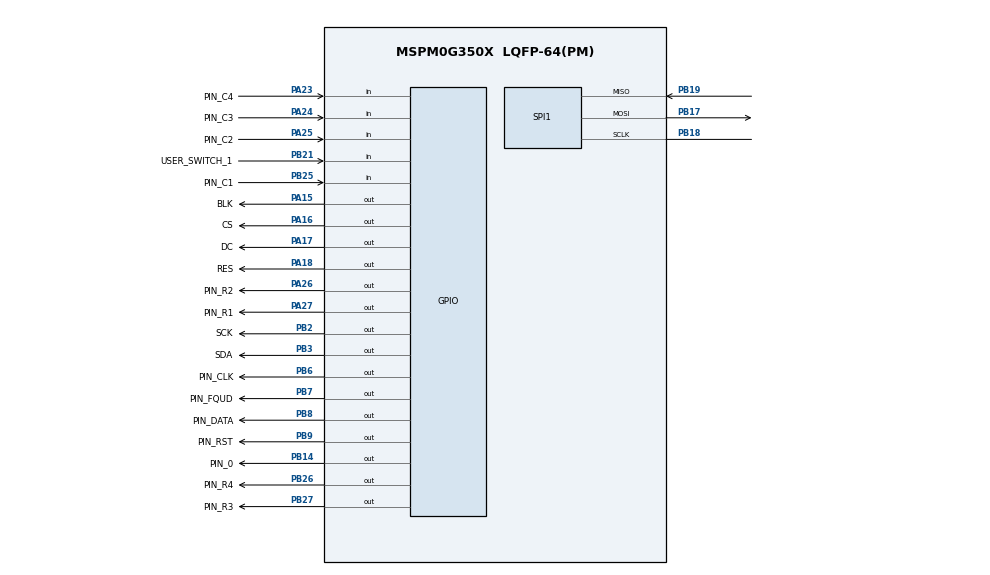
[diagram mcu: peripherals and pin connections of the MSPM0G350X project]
/**
 *
 * @cliArgs --device "MSPM0G350X" --part "Default" --package "LQFP-64(PM)" --product "mspm0_sdk@2.11.00.07"
 * @versions {"tool":"1.28.0+4696"}
 */

/**
 * Import the modules used in this configuration.
 */
const GPIO    = scripting.addModule("/ti/driverlib/GPIO", {}, false);
const GPIO1   = GPIO.addInstance();
const GPIO2   = GPIO.addInstance();
const GPIO3   = GPIO.addInstance();
const GPIO4   = GPIO.addInstance();
const GPIO5   = GPIO.addInstance();
const GPIO6   = GPIO.addInstance();
const SPI     = scripting.addModule("/ti/driverlib/SPI", {}, false);
const SPI1    = SPI.addInstance();
const SYSCTL  = scripting.addModule("/ti/driverlib/SYSCTL");
const SYSTICK = scripting.addModule("/ti/driverlib/SYSTICK");

/**
 * Write custom configuration values to the imported modules.
 */
GPIO1.$name                         = "GPIO_DDS";
GPIO1.associatedPins.create(4);
GPIO1.associatedPins[0].$name       = "PIN_CLK";
GPIO1.associatedPins[0].pin.$assign = "PB6";
GPIO1.associatedPins[1].$name       = "PIN_FQUD";
GPIO1.associatedPins[1].pin.$assign = "PB7";
GPIO1.associatedPins[2].$name       = "PIN_DATA";
GPIO1.associatedPins[2].pin.$assign = "PB8";
GPIO1.associatedPins[3].$name       = "PIN_RST";
GPIO1.associatedPins[3].pin.$assign = "PB9";

const Board = scripting.addModule("/ti/driverlib/Board", {}, false);

GPIO2.$name                         = "GPIO_USRLED";
GPIO2.associatedPins[0].$name       = "PIN_0";
GPIO2.associatedPins[0].pin.$assign = "PB14";

GPIO3.$name                              = "GPIO_KEYMATRIX";
GPIO3.associatedPins.create(8);
GPIO3.associatedPins[0].$name            = "PIN_R1";
GPIO3.associatedPins[0].initialValue     = "SET";
GPIO3.associatedPins[0].pin.$assign      = "PA27";
GPIO3.associatedPins[1].$name            = "PIN_R2";
GPIO3.associatedPins[1].initialValue     = "SET";
GPIO3.associatedPins[1].pin.$assign      = "PA26";
GPIO3.associatedPins[2].$name            = "PIN_R3";
GPIO3.associatedPins[2].initialValue     = "SET";
GPIO3.associatedPins[2].pin.$assign      = "PB27";
GPIO3.associatedPins[3].internalResistor = "PULL_UP";
GPIO3.associatedPins[3].$name            = "PIN_R4";
GPIO3.associatedPins[3].initialValue     = "SET";
GPIO3.associatedPins[3].pin.$assign      = "PB26";
GPIO3.associatedPins[4].direction        = "INPUT";
GPIO3.associatedPins[4].internalResistor = "PULL_UP";
GPIO3.associatedPins[4].$name            = "PIN_C1";
GPIO3.associatedPins[4].pin.$assign      = "PB25";
GPIO3.associatedPins[5].direction        = "INPUT";
GPIO3.associatedPins[5].internalResistor = "PULL_UP";
GPIO3.associatedPins[5].$name            = "PIN_C2";
GPIO3.associatedPins[5].pin.$assign      = "PA25";
GPIO3.associatedPins[6].$name            = "PIN_C3";
GPIO3.associatedPins[6].direction        = "INPUT";
GPIO3.associatedPins[6].internalResistor = "PULL_UP";
GPIO3.associatedPins[6].pin.$assign      = "PA24";
GPIO3.associatedPins[7].$name            = "PIN_C4";
GPIO3.associatedPins[7].direction        = "INPUT";
GPIO3.associatedPins[7].internalResistor = "PULL_UP";
GPIO3.associatedPins[7].pin.$assign      = "PA23";

GPIO4.$name                              = "GPIO_SWITCHES";
GPIO4.associatedPins[0].$name            = "USER_SWITCH_1";
GPIO4.associatedPins[0].direction        = "INPUT";
GPIO4.associatedPins[0].internalResistor = "PULL_UP";
GPIO4.associatedPins[0].pin.$assign      = "PB21";

GPIO5.$name                          = "LCD";
GPIO5.associatedPins.create(4);
GPIO5.associatedPins[0].$name        = "RES";
GPIO5.associatedPins[0].pin.$assign  = "PA18";
GPIO5.associatedPins[1].$name        = "DC";
GPIO5.associatedPins[1].pin.$assign  = "PA17";
GPIO5.associatedPins[2].$name        = "CS";
GPIO5.associatedPins[2].initialValue = "SET";
GPIO5.associatedPins[2].pin.$assign  = "PA16";
GPIO5.associatedPins[3].$name        = "BLK";
GPIO5.associatedPins[3].initialValue = "SET";
GPIO5.associatedPins[3].pin.$assign  = "PA15";

GPIO6.$name                              = "GPIO_I2C";
GPIO6.associatedPins.create(2);
GPIO6.associatedPins[0].$name            = "SCK";
GPIO6.associatedPins[0].internalResistor = "PULL_UP";
GPIO6.associatedPins[0].initialValue     = "SET";
GPIO6.associatedPins[0].pin.$assign      = "PB2";
GPIO6.associatedPins[1].$name            = "SDA";
GPIO6.associatedPins[1].internalResistor = "PULL_UP";
GPIO6.associatedPins[1].initialValue     = "SET";
GPIO6.associatedPins[1].pin.$assign      = "PB3";

SPI1.$name                              = "SPI_LCD";
SPI1.frameFormat                        = "MOTO3";
SPI1.sclkPinConfig.$name                = "ti_driverlib_gpio_GPIOPinGeneric2";
SPI1.sclkPinConfig.direction            = scripting.forceWrite("OUTPUT");
SPI1.sclkPinConfig.onlyInternalResistor = scripting.forceWrite(false);
SPI1.sclkPinConfig.passedPeripheralType = scripting.forceWrite("Digital");
SPI1.mosiPinConfig.$name                = "ti_driverlib_gpio_GPIOPinGeneric3";
SPI1.mosiPinConfig.direction            = scripting.forceWrite("OUTPUT");
SPI1.mosiPinConfig.hideOutputInversion  = scripting.forceWrite(false);
SPI1.mosiPinConfig.onlyInternalResistor = scripting.forceWrite(false);
SPI1.mosiPinConfig.passedPeripheralType = scripting.forceWrite("Digital");
SPI1.misoPinConfig.$name                = "ti_driverlib_gpio_GPIOPinGeneric4";
SPI1.misoPinConfig.onlyInternalResistor = scripting.forceWrite(false);
SPI1.misoPinConfig.passedPeripheralType = scripting.forceWrite("Digital");
SPI1.peripheral.sclkPin.$assign         = "PB18";
SPI1.peripheral.mosiPin.$assign         = "PB17";
SPI1.peripheral.misoPin.$assign         = "PB19";

SYSCTL.forceDefaultClkConfig = true;

SYSTICK.periodEnable  = true;
SYSTICK.period        = 32000;
SYSTICK.systickEnable = true;

/**
 * Pinmux solution for unlocked pins/peripherals. This ensures that minor changes to the automatic solver in a future
 * version of the tool will not impact the pinmux you originally saw.  These lines can be completely deleted in order to
 * re-solve from scratch.
 */
Board.peripheral.$suggestSolution          = "DEBUGSS";
Board.peripheral.swclkPin.$suggestSolution = "PA20";
Board.peripheral.swdioPin.$suggestSolution = "PA19";
SPI1.peripheral.$suggestSolution           = "SPI0";
SYSCTL.peripheral.$suggestSolution         = "SYSCTL";
